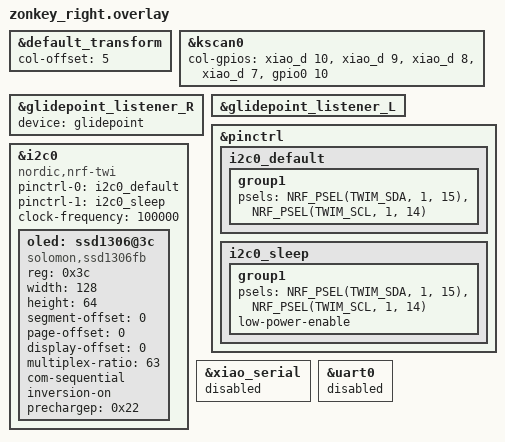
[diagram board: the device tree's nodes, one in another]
#include "zonkey.dtsi"

/* ---------- matrix ---------- */

&default_transform {
    col-offset = <5>;
};

&kscan0 {
    col-gpios =
          <&xiao_d 10 GPIO_ACTIVE_HIGH>
        , <&xiao_d 9  GPIO_ACTIVE_HIGH>
        , <&xiao_d 8  GPIO_ACTIVE_HIGH>
        , <&xiao_d 7  GPIO_ACTIVE_HIGH>
        , <&gpio0   10 GPIO_ACTIVE_HIGH>
        ;
};

/* ---------- trackpad (glidepoint) ---------- */

&glidepoint_listener_R {
    status = "okay";
    device = <&glidepoint>;
};

&glidepoint_listener_L {
    status = "okay";
};

/* ---------- pinctrl (ONE BLOCK ONLY) ---------- */

&pinctrl {
    /* I2C0 for OLED */
    i2c0_default: i2c0_default {
        group1 {
            psels =
                <NRF_PSEL(TWIM_SDA, 1, 15)>,
                <NRF_PSEL(TWIM_SCL, 1, 14)>;
        };
    };

    i2c0_sleep: i2c0_sleep {
        group1 {
            psels =
                <NRF_PSEL(TWIM_SDA, 1, 15)>,
                <NRF_PSEL(TWIM_SCL, 1, 14)>;
            low-power-enable;
        };
    };
};

/* ---------- I2C0 + OLED ---------- */

&i2c0 {
    status = "okay";
    compatible = "nordic,nrf-twi";
    pinctrl-0 = <&i2c0_default>;
    pinctrl-1 = <&i2c0_sleep>;
    pinctrl-names = "default", "sleep";
    clock-frequency = <100000>;

    oled: ssd1306@3c {
        compatible = "solomon,ssd1306fb";
        reg = <0x3c>;
        width = <128>;
        height = <64>;   /* ← 修正 */
        segment-offset = <0>;
        page-offset = <0>;
        display-offset = <0>;
        multiplex-ratio = <63>;
        com-sequential;
        inversion-on;
        prechargep = <0x22>;
    };
};

/* ---------- disable unused ---------- */

&xiao_serial { status = "disabled"; };
&uart0       { status = "disabled"; };
